VERSION ""

NS_ :

BS_:

BU_:

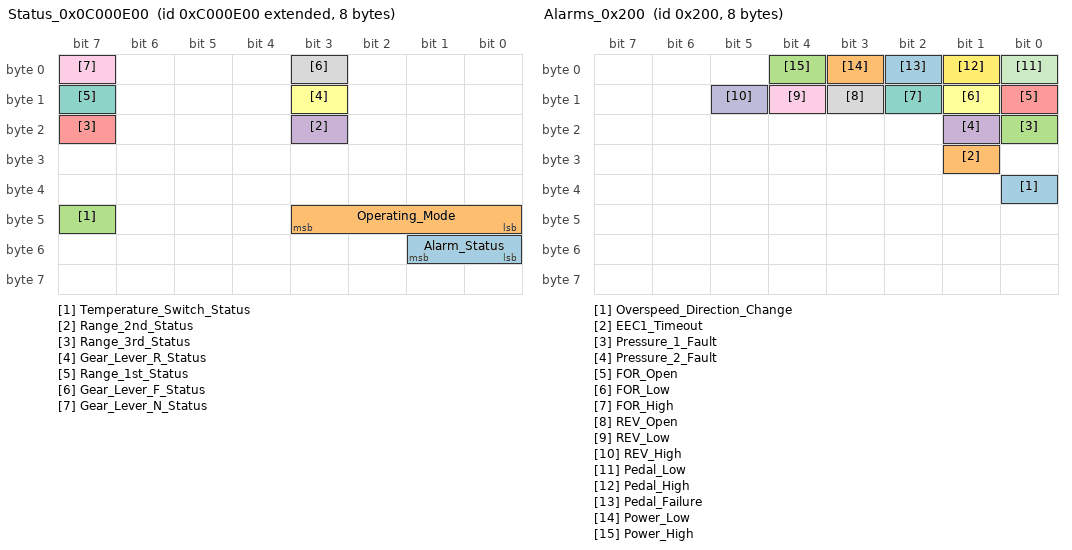
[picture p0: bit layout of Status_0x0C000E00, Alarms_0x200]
BO_ 2348813824 Status_0x0C000E00: 8 TCU
 SG_ Alarm_Status : 49|2@0+ (1,0) [0|3] "" Vector__XXX
 SG_ Operating_Mode : 43|4@0+ (1,0) [0|15] "" Vector__XXX
 SG_ Temperature_Switch_Status : 47|1@0+ (1,0) [0|1] "" Vector__XXX
 SG_ Range_2nd_Status : 19|1@0+ (1,0) [0|1] "" Vector__XXX
 SG_ Range_3rd_Status : 23|1@0+ (1,0) [0|1] "" Vector__XXX
 SG_ Gear_Lever_R_Status : 11|1@0+ (1,0) [0|1] "" Vector__XXX
 SG_ Range_1st_Status : 15|1@0+ (1,0) [0|1] "" Vector__XXX
 SG_ Gear_Lever_F_Status : 3|1@0+ (1,0) [0|1] "" Vector__XXX
 SG_ Gear_Lever_N_Status : 7|1@0+ (1,0) [0|1] "" Vector__XXX

BO_ 512 Alarms_0x200: 8 TCU
 SG_ Overspeed_Direction_Change : 32|1@0+ (1,0) [0|1] "" Vector__XXX
 SG_ EEC1_Timeout : 25|1@0+ (1,0) [0|1] "" Vector__XXX
 SG_ Pressure_1_Fault : 16|1@0+ (1,0) [0|1] "" Vector__XXX
 SG_ Pressure_2_Fault : 17|1@0+ (1,0) [0|1] "" Vector__XXX
 SG_ FOR_Open : 8|1@0+ (1,0) [0|1] "" Vector__XXX
 SG_ FOR_Low : 9|1@0+ (1,0) [0|1] "" Vector__XXX
 SG_ FOR_High : 10|1@0+ (1,0) [0|1] "" Vector__XXX
 SG_ REV_Open : 11|1@0+ (1,0) [0|1] "" Vector__XXX
 SG_ REV_Low : 12|1@0+ (1,0) [0|1] "" Vector__XXX
 SG_ REV_High : 13|1@0+ (1,0) [0|1] "" Vector__XXX
 SG_ Pedal_Low : 0|1@0+ (1,0) [0|1] "" Vector__XXX
 SG_ Pedal_High : 1|1@0+ (1,0) [0|1] "" Vector__XXX
 SG_ Pedal_Failure : 2|1@0+ (1,0) [0|1] "" Vector__XXX
 SG_ Power_Low : 3|1@0+ (1,0) [0|1] "" Vector__XXX
 SG_ Power_High : 4|1@0+ (1,0) [0|1] "" Vector__XXX

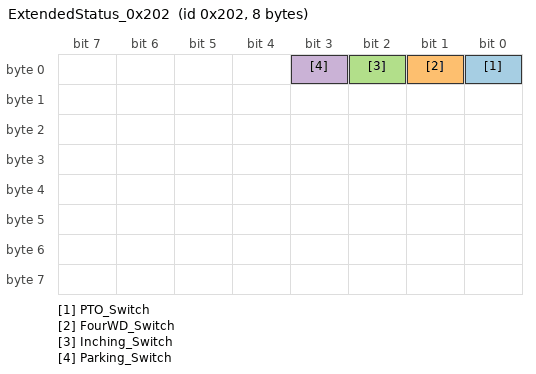
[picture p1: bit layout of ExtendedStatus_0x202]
BO_ 514 ExtendedStatus_0x202: 8 TCU
 SG_ PTO_Switch : 0|1@0+ (1,0) [0|1] "" Vector__XXX
 SG_ FourWD_Switch : 1|1@0+ (1,0) [0|1] "" Vector__XXX
 SG_ Inching_Switch : 2|1@0+ (1,0) [0|1] "" Vector__XXX
 SG_ Parking_Switch : 3|1@0+ (1,0) [0|1] "" Vector__XXX

BA_DEF_ BO_  "GenMsgCycleTime" INT 0 65535;
BA_DEF_DEF_  "GenMsgCycleTime" 0;
BA_ "GenMsgCycleTime" BO_ 2348813824 100;
BA_ "GenMsgCycleTime" BO_ 512 1000;
BA_ "GenMsgCycleTime" BO_ 514 100;
